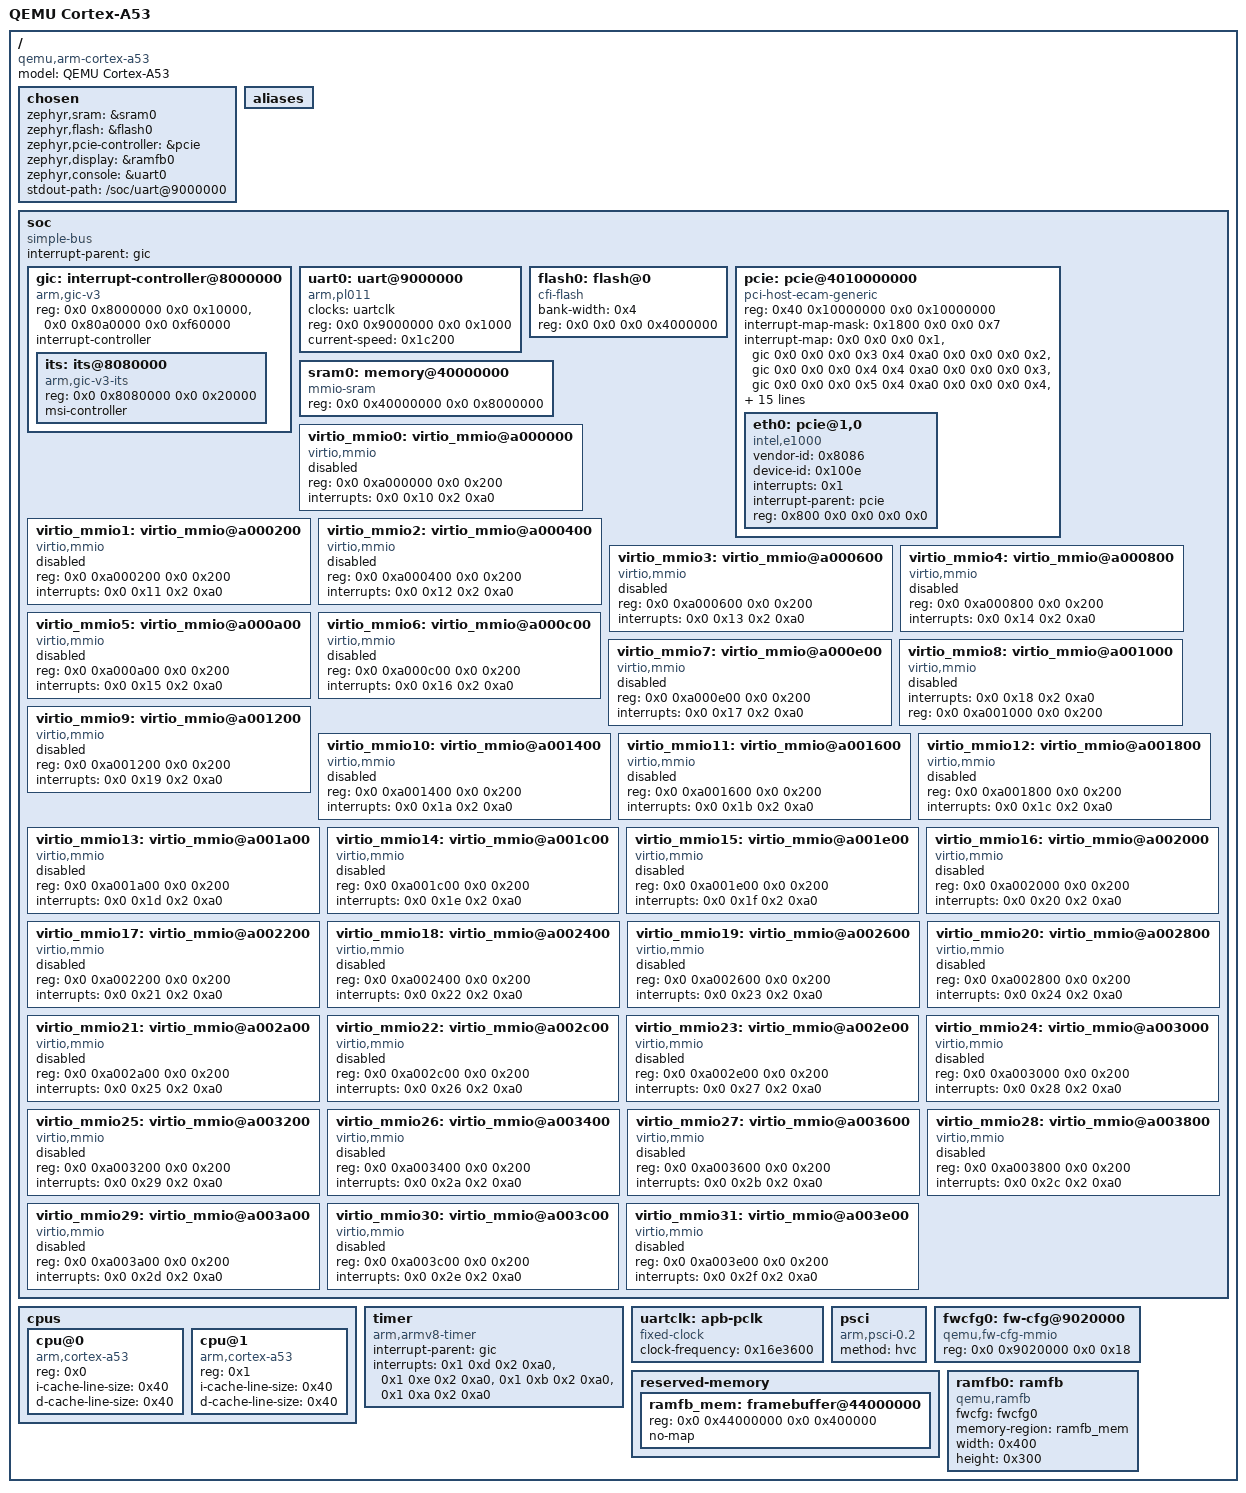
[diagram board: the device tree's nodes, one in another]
/dts-v1/;

/* node '/' defined in zephyr/dts/common/skeleton.dtsi:9 */
/ {
	#address-cells = < 0x2 >;           /* in zephyr/dts/arm64/qemu/qemu-virt-a53.dtsi:22 */
	#size-cells = < 0x2 >;              /* in zephyr/dts/arm64/qemu/qemu-virt-a53.dtsi:23 */
	model = "QEMU Cortex-A53";          /* in zephyr/boards/qemu/cortex_a53/qemu_cortex_a53.dts:12 */
	compatible = "qemu,arm-cortex-a53"; /* in zephyr/boards/qemu/cortex_a53/qemu_cortex_a53.dts:13 */

	/* node '/chosen' defined in zephyr/dts/common/skeleton.dtsi:13 */
	chosen {
		zephyr,sram = &sram0;              /* in zephyr/boards/qemu/cortex_a53/qemu_cortex_a53.dts:21 */
		zephyr,flash = &flash0;            /* in zephyr/boards/qemu/cortex_a53/qemu_cortex_a53.dts:24 */
		zephyr,pcie-controller = &pcie;    /* in zephyr/boards/qemu/cortex_a53/qemu_cortex_a53.dts:25 */
		zephyr,display = &ramfb0;          /* in zephyr/boards/qemu/cortex_a53/qemu_cortex_a53.dts:26 */
		zephyr,console = &uart0;           /* in ../../../../mnt/f/project/泉城实验室/tgoskits/configs/contest/zephyr/qemu-cortex-a53-pl011-polling.overlay:8 */
		stdout-path = "/soc/uart@9000000"; /* in ../../../../mnt/f/project/泉城实验室/tgoskits/configs/contest/zephyr/qemu-cortex-a53-pl011-polling.overlay:10 */
	};

	/* node '/aliases' defined in zephyr/dts/common/skeleton.dtsi:15 */
	aliases {
	};

	/* node '/soc' defined in zephyr/dts/arm64/armv8-a.dtsi:10 */
	soc {
		compatible = "simple-bus";   /* in zephyr/dts/arm64/armv8-a.dtsi:13 */
		#address-cells = < 0x2 >;    /* in zephyr/dts/arm64/qemu/qemu-virt-a53.dtsi:66 */
		#size-cells = < 0x2 >;       /* in zephyr/dts/arm64/qemu/qemu-virt-a53.dtsi:67 */
		ranges;                      /* in zephyr/dts/arm64/qemu/qemu-virt-a53.dtsi:68 */
		interrupt-parent = < &gic >; /* in zephyr/dts/arm64/qemu/qemu-virt-a53.dtsi:70 */

		/* node '/soc/interrupt-controller@8000000' defined in zephyr/dts/arm64/qemu/qemu-virt-a53.dtsi:72 */
		gic: interrupt-controller@8000000 {
			compatible = "arm,gic-v3",
			             "arm,gic";               /* in zephyr/dts/arm64/qemu/qemu-virt-a53.dtsi:73 */
			reg = < 0x0 0x8000000 0x0 0x10000 >,
			      < 0x0 0x80a0000 0x0 0xf60000 >; /* in zephyr/dts/arm64/qemu/qemu-virt-a53.dtsi:74 */
			interrupt-controller;                 /* in zephyr/dts/arm64/qemu/qemu-virt-a53.dtsi:76 */
			#interrupt-cells = < 0x4 >;           /* in zephyr/dts/arm64/qemu/qemu-virt-a53.dtsi:77 */
			status = "okay";                      /* in zephyr/dts/arm64/qemu/qemu-virt-a53.dtsi:78 */
			#size-cells = < 0x2 >;                /* in zephyr/dts/arm64/qemu/qemu-virt-a53.dtsi:79 */
			#address-cells = < 0x2 >;             /* in zephyr/dts/arm64/qemu/qemu-virt-a53.dtsi:80 */
			phandle = < 0x1 >;                    /* in zephyr/dts/arm64/qemu/qemu-virt-a53.dtsi:70 */

			/* node '/soc/interrupt-controller@8000000/its@8080000' defined in zephyr/dts/arm64/qemu/qemu-virt-a53.dtsi:82 */
			its: its@8080000 {
				compatible = "arm,gic-v3-its";       /* in zephyr/dts/arm64/qemu/qemu-virt-a53.dtsi:83 */
				reg = < 0x0 0x8080000 0x0 0x20000 >; /* in zephyr/dts/arm64/qemu/qemu-virt-a53.dtsi:84 */
				msi-controller;                      /* in zephyr/dts/arm64/qemu/qemu-virt-a53.dtsi:85 */
				phandle = < 0x3 >;                   /* in zephyr/dts/arm64/qemu/qemu-virt-a53.dtsi:151 */
			};
		};

		/* node '/soc/uart@9000000' defined in zephyr/dts/arm64/qemu/qemu-virt-a53.dtsi:89 */
		uart0: uart@9000000 {
			clocks = < &uartclk >;              /* in zephyr/dts/arm64/qemu/qemu-virt-a53.dtsi:95 */
			compatible = "arm,pl011";           /* in ../../../../mnt/f/project/泉城实验室/tgoskits/configs/contest/zephyr/qemu-cortex-a53-pl011-polling.overlay:15 */
			reg = < 0x0 0x9000000 0x0 0x1000 >; /* in ../../../../mnt/f/project/泉城实验室/tgoskits/configs/contest/zephyr/qemu-cortex-a53-pl011-polling.overlay:16 */
			current-speed = < 0x1c200 >;        /* in ../../../../mnt/f/project/泉城实验室/tgoskits/configs/contest/zephyr/qemu-cortex-a53-pl011-polling.overlay:17 */
			status = "okay";                    /* in ../../../../mnt/f/project/泉城实验室/tgoskits/configs/contest/zephyr/qemu-cortex-a53-pl011-polling.overlay:18 */
		};

		/* node '/soc/flash@0' defined in zephyr/dts/arm64/qemu/qemu-virt-a53.dtsi:98 */
		flash0: flash@0 {
			compatible = "cfi-flash";        /* in zephyr/dts/arm64/qemu/qemu-virt-a53.dtsi:99 */
			bank-width = < 0x4 >;            /* in zephyr/dts/arm64/qemu/qemu-virt-a53.dtsi:100 */
			reg = < 0x0 0x0 0x0 0x4000000 >; /* in zephyr/dts/arm64/qemu/qemu-virt-a53.dtsi:105 */
		};

		/* node '/soc/pcie@4010000000' defined in zephyr/dts/arm64/qemu/qemu-virt-a53.dtsi:108 */
		pcie: pcie@4010000000 {
			compatible = "pci-host-ecam-generic";                                                                 /* in zephyr/dts/arm64/qemu/qemu-virt-a53.dtsi:109 */
			device_type = "pci";                                                                                  /* in zephyr/dts/arm64/qemu/qemu-virt-a53.dtsi:110 */
			reg = < 0x40 0x10000000 0x0 0x10000000 >;                                                             /* in zephyr/dts/arm64/qemu/qemu-virt-a53.dtsi:111 */
			#size-cells = < 0x2 >;                                                                                /* in zephyr/dts/arm64/qemu/qemu-virt-a53.dtsi:112 */
			#address-cells = < 0x3 >;                                                                             /* in zephyr/dts/arm64/qemu/qemu-virt-a53.dtsi:113 */
			ranges = < 0x1000000 0x0 0x0 0x0 0x3eff0000 0x0 0x10000 0x2000000 0x0 0x10000000 0x0 0x10000000
			           0x0 0x2eff0000 0x3000000 0x80 0x0 0x80 0x0 0x80 0x0 >;                                     /* in zephyr/dts/arm64/qemu/qemu-virt-a53.dtsi:114 */
			#interrupt-cells = < 0x1 >;                                                                           /* in zephyr/dts/arm64/qemu/qemu-virt-a53.dtsi:117 */
			interrupt-map-mask = < 0x1800 0x0 0x0 0x7 >;                                                          /* in zephyr/dts/arm64/qemu/qemu-virt-a53.dtsi:118 */
			interrupt-map = < 0x0 0x0 0x0 0x1 &gic 0x0 0x0 0x0 0x3 0x4 0xa0 0x0 0x0 0x0 0x2 &gic 0x0 0x0 0x0 0x4
			                  0x4 0xa0 0x0 0x0 0x0 0x3 &gic 0x0 0x0 0x0 0x5 0x4 0xa0 0x0 0x0 0x0 0x4 &gic 0x0 0x0
			                  0x0 0x6 0x4 0xa0 0x800 0x0 0x0 0x1 &gic 0x0 0x0 0x0 0x4 0x4 0xa0 0x800 0x0 0x0 0x2
			                  &gic 0x0 0x0 0x0 0x5 0x4 0xa0 0x800 0x0 0x0 0x3 &gic 0x0 0x0 0x0 0x6 0x4 0xa0 0x800
			                  0x0 0x0 0x4 &gic 0x0 0x0 0x0 0x3 0x4 0xa0 0x1000 0x0 0x0 0x1 &gic 0x0 0x0 0x0 0x5
			                  0x4 0xa0 0x1000 0x0 0x0 0x2 &gic 0x0 0x0 0x0 0x6 0x4 0xa0 0x1000 0x0 0x0 0x3 &gic
			                  0x0 0x0 0x0 0x3 0x4 0xa0 0x1000 0x0 0x0 0x4 &gic 0x0 0x0 0x0 0x4 0x4 0xa0 0x1800
			                  0x0 0x0 0x1 &gic 0x0 0x0 0x0 0x6 0x4 0xa0 0x1800 0x0 0x0 0x2 &gic 0x0 0x0 0x0 0x3
			                  0x4 0xa0 0x1800 0x0 0x0 0x3 &gic 0x0 0x0 0x0 0x4 0x4 0xa0 0x1800 0x0 0x0 0x4 &gic
			                  0x0 0x0 0x0 0x5 0x4 0xa0 >;                                                         /* in zephyr/dts/arm64/qemu/qemu-virt-a53.dtsi:119 */
			msi-parent = < &its >;                                                                                /* in zephyr/dts/arm64/qemu/qemu-virt-a53.dtsi:151 */
			bus-range = < 0x0 0xff >;                                                                             /* in zephyr/dts/arm64/qemu/qemu-virt-a53.dtsi:152 */
			phandle = < 0x4 >;                                                                                    /* in zephyr/boards/qemu/cortex_a53/qemu_cortex_a53.dts:298 */

			/* node '/soc/pcie@4010000000/pcie@1,0' defined in zephyr/boards/qemu/cortex_a53/qemu_cortex_a53.dts:293 */
			eth0: pcie@1,0 {
				compatible = "intel,e1000";      /* in zephyr/boards/qemu/cortex_a53/qemu_cortex_a53.dts:294 */
				vendor-id = < 0x8086 >;          /* in zephyr/boards/qemu/cortex_a53/qemu_cortex_a53.dts:295 */
				device-id = < 0x100e >;          /* in zephyr/boards/qemu/cortex_a53/qemu_cortex_a53.dts:296 */
				interrupts = < 0x1 >;            /* in zephyr/boards/qemu/cortex_a53/qemu_cortex_a53.dts:297 */
				interrupt-parent = < &pcie >;    /* in zephyr/boards/qemu/cortex_a53/qemu_cortex_a53.dts:298 */
				reg = < 0x800 0x0 0x0 0x0 0x0 >; /* in zephyr/boards/qemu/cortex_a53/qemu_cortex_a53.dts:299 */
				status = "okay";                 /* in zephyr/boards/qemu/cortex_a53/qemu_cortex_a53.dts:300 */
			};
		};

		/* node '/soc/memory@40000000' defined in zephyr/boards/qemu/cortex_a53/qemu_cortex_a53.dts:30 */
		sram0: memory@40000000 {
			compatible = "mmio-sram";               /* in zephyr/boards/qemu/cortex_a53/qemu_cortex_a53.dts:31 */
			reg = < 0x0 0x40000000 0x0 0x8000000 >; /* in zephyr/boards/qemu/cortex_a53/qemu_cortex_a53.dts:32 */
		};

		/* node '/soc/virtio_mmio@a000000' defined in zephyr/boards/qemu/cortex_a53/qemu_cortex_a53.dts:35 */
		virtio_mmio0: virtio_mmio@a000000 {
			compatible = "virtio,mmio";         /* in zephyr/boards/qemu/cortex_a53/qemu_cortex_a53.dts:36 */
			reg = < 0x0 0xa000000 0x0 0x200 >;  /* in zephyr/boards/qemu/cortex_a53/qemu_cortex_a53.dts:37 */
			interrupts = < 0x0 0x10 0x2 0xa0 >; /* in zephyr/boards/qemu/cortex_a53/qemu_cortex_a53.dts:38 */
			status = "disabled";                /* in zephyr/boards/qemu/cortex_a53/qemu_cortex_a53.dts:39 */
		};

		/* node '/soc/virtio_mmio@a000200' defined in zephyr/boards/qemu/cortex_a53/qemu_cortex_a53.dts:42 */
		virtio_mmio1: virtio_mmio@a000200 {
			compatible = "virtio,mmio";         /* in zephyr/boards/qemu/cortex_a53/qemu_cortex_a53.dts:43 */
			reg = < 0x0 0xa000200 0x0 0x200 >;  /* in zephyr/boards/qemu/cortex_a53/qemu_cortex_a53.dts:44 */
			interrupts = < 0x0 0x11 0x2 0xa0 >; /* in zephyr/boards/qemu/cortex_a53/qemu_cortex_a53.dts:45 */
			status = "disabled";                /* in zephyr/boards/qemu/cortex_a53/qemu_cortex_a53.dts:46 */
		};

		/* node '/soc/virtio_mmio@a000400' defined in zephyr/boards/qemu/cortex_a53/qemu_cortex_a53.dts:49 */
		virtio_mmio2: virtio_mmio@a000400 {
			compatible = "virtio,mmio";         /* in zephyr/boards/qemu/cortex_a53/qemu_cortex_a53.dts:50 */
			reg = < 0x0 0xa000400 0x0 0x200 >;  /* in zephyr/boards/qemu/cortex_a53/qemu_cortex_a53.dts:51 */
			interrupts = < 0x0 0x12 0x2 0xa0 >; /* in zephyr/boards/qemu/cortex_a53/qemu_cortex_a53.dts:52 */
			status = "disabled";                /* in zephyr/boards/qemu/cortex_a53/qemu_cortex_a53.dts:53 */
		};

		/* node '/soc/virtio_mmio@a000600' defined in zephyr/boards/qemu/cortex_a53/qemu_cortex_a53.dts:56 */
		virtio_mmio3: virtio_mmio@a000600 {
			compatible = "virtio,mmio";         /* in zephyr/boards/qemu/cortex_a53/qemu_cortex_a53.dts:57 */
			reg = < 0x0 0xa000600 0x0 0x200 >;  /* in zephyr/boards/qemu/cortex_a53/qemu_cortex_a53.dts:58 */
			interrupts = < 0x0 0x13 0x2 0xa0 >; /* in zephyr/boards/qemu/cortex_a53/qemu_cortex_a53.dts:59 */
			status = "disabled";                /* in zephyr/boards/qemu/cortex_a53/qemu_cortex_a53.dts:60 */
		};

		/* node '/soc/virtio_mmio@a000800' defined in zephyr/boards/qemu/cortex_a53/qemu_cortex_a53.dts:63 */
		virtio_mmio4: virtio_mmio@a000800 {
			compatible = "virtio,mmio";         /* in zephyr/boards/qemu/cortex_a53/qemu_cortex_a53.dts:64 */
			reg = < 0x0 0xa000800 0x0 0x200 >;  /* in zephyr/boards/qemu/cortex_a53/qemu_cortex_a53.dts:65 */
			interrupts = < 0x0 0x14 0x2 0xa0 >; /* in zephyr/boards/qemu/cortex_a53/qemu_cortex_a53.dts:66 */
			status = "disabled";                /* in zephyr/boards/qemu/cortex_a53/qemu_cortex_a53.dts:67 */
		};

		/* node '/soc/virtio_mmio@a000a00' defined in zephyr/boards/qemu/cortex_a53/qemu_cortex_a53.dts:70 */
		virtio_mmio5: virtio_mmio@a000a00 {
			compatible = "virtio,mmio";         /* in zephyr/boards/qemu/cortex_a53/qemu_cortex_a53.dts:71 */
			reg = < 0x0 0xa000a00 0x0 0x200 >;  /* in zephyr/boards/qemu/cortex_a53/qemu_cortex_a53.dts:72 */
			interrupts = < 0x0 0x15 0x2 0xa0 >; /* in zephyr/boards/qemu/cortex_a53/qemu_cortex_a53.dts:73 */
			status = "disabled";                /* in zephyr/boards/qemu/cortex_a53/qemu_cortex_a53.dts:74 */
		};

		/* node '/soc/virtio_mmio@a000c00' defined in zephyr/boards/qemu/cortex_a53/qemu_cortex_a53.dts:77 */
		virtio_mmio6: virtio_mmio@a000c00 {
			compatible = "virtio,mmio";         /* in zephyr/boards/qemu/cortex_a53/qemu_cortex_a53.dts:78 */
			reg = < 0x0 0xa000c00 0x0 0x200 >;  /* in zephyr/boards/qemu/cortex_a53/qemu_cortex_a53.dts:79 */
			interrupts = < 0x0 0x16 0x2 0xa0 >; /* in zephyr/boards/qemu/cortex_a53/qemu_cortex_a53.dts:80 */
			status = "disabled";                /* in zephyr/boards/qemu/cortex_a53/qemu_cortex_a53.dts:81 */
		};

		/* node '/soc/virtio_mmio@a000e00' defined in zephyr/boards/qemu/cortex_a53/qemu_cortex_a53.dts:84 */
		virtio_mmio7: virtio_mmio@a000e00 {
			compatible = "virtio,mmio";         /* in zephyr/boards/qemu/cortex_a53/qemu_cortex_a53.dts:85 */
			reg = < 0x0 0xa000e00 0x0 0x200 >;  /* in zephyr/boards/qemu/cortex_a53/qemu_cortex_a53.dts:86 */
			interrupts = < 0x0 0x17 0x2 0xa0 >; /* in zephyr/boards/qemu/cortex_a53/qemu_cortex_a53.dts:87 */
			status = "disabled";                /* in zephyr/boards/qemu/cortex_a53/qemu_cortex_a53.dts:88 */
		};

		/* node '/soc/virtio_mmio@a001000' defined in zephyr/boards/qemu/cortex_a53/qemu_cortex_a53.dts:91 */
		virtio_mmio8: virtio_mmio@a001000 {
			compatible = "virtio,mmio";         /* in zephyr/boards/qemu/cortex_a53/qemu_cortex_a53.dts:92 */
			interrupts = < 0x0 0x18 0x2 0xa0 >; /* in zephyr/boards/qemu/cortex_a53/qemu_cortex_a53.dts:93 */
			reg = < 0x0 0xa001000 0x0 0x200 >;  /* in zephyr/boards/qemu/cortex_a53/qemu_cortex_a53.dts:94 */
			status = "disabled";                /* in zephyr/boards/qemu/cortex_a53/qemu_cortex_a53.dts:95 */
		};

		/* node '/soc/virtio_mmio@a001200' defined in zephyr/boards/qemu/cortex_a53/qemu_cortex_a53.dts:98 */
		virtio_mmio9: virtio_mmio@a001200 {
			compatible = "virtio,mmio";         /* in zephyr/boards/qemu/cortex_a53/qemu_cortex_a53.dts:99 */
			reg = < 0x0 0xa001200 0x0 0x200 >;  /* in zephyr/boards/qemu/cortex_a53/qemu_cortex_a53.dts:100 */
			interrupts = < 0x0 0x19 0x2 0xa0 >; /* in zephyr/boards/qemu/cortex_a53/qemu_cortex_a53.dts:101 */
			status = "disabled";                /* in zephyr/boards/qemu/cortex_a53/qemu_cortex_a53.dts:102 */
		};

		/* node '/soc/virtio_mmio@a001400' defined in zephyr/boards/qemu/cortex_a53/qemu_cortex_a53.dts:105 */
		virtio_mmio10: virtio_mmio@a001400 {
			compatible = "virtio,mmio";         /* in zephyr/boards/qemu/cortex_a53/qemu_cortex_a53.dts:106 */
			reg = < 0x0 0xa001400 0x0 0x200 >;  /* in zephyr/boards/qemu/cortex_a53/qemu_cortex_a53.dts:107 */
			interrupts = < 0x0 0x1a 0x2 0xa0 >; /* in zephyr/boards/qemu/cortex_a53/qemu_cortex_a53.dts:108 */
			status = "disabled";                /* in zephyr/boards/qemu/cortex_a53/qemu_cortex_a53.dts:109 */
		};

		/* node '/soc/virtio_mmio@a001600' defined in zephyr/boards/qemu/cortex_a53/qemu_cortex_a53.dts:112 */
		virtio_mmio11: virtio_mmio@a001600 {
			compatible = "virtio,mmio";         /* in zephyr/boards/qemu/cortex_a53/qemu_cortex_a53.dts:113 */
			reg = < 0x0 0xa001600 0x0 0x200 >;  /* in zephyr/boards/qemu/cortex_a53/qemu_cortex_a53.dts:114 */
			interrupts = < 0x0 0x1b 0x2 0xa0 >; /* in zephyr/boards/qemu/cortex_a53/qemu_cortex_a53.dts:115 */
			status = "disabled";                /* in zephyr/boards/qemu/cortex_a53/qemu_cortex_a53.dts:116 */
		};

		/* node '/soc/virtio_mmio@a001800' defined in zephyr/boards/qemu/cortex_a53/qemu_cortex_a53.dts:119 */
		virtio_mmio12: virtio_mmio@a001800 {
			compatible = "virtio,mmio";         /* in zephyr/boards/qemu/cortex_a53/qemu_cortex_a53.dts:120 */
			reg = < 0x0 0xa001800 0x0 0x200 >;  /* in zephyr/boards/qemu/cortex_a53/qemu_cortex_a53.dts:121 */
			interrupts = < 0x0 0x1c 0x2 0xa0 >; /* in zephyr/boards/qemu/cortex_a53/qemu_cortex_a53.dts:122 */
			status = "disabled";                /* in zephyr/boards/qemu/cortex_a53/qemu_cortex_a53.dts:123 */
		};

		/* node '/soc/virtio_mmio@a001a00' defined in zephyr/boards/qemu/cortex_a53/qemu_cortex_a53.dts:126 */
		virtio_mmio13: virtio_mmio@a001a00 {
			compatible = "virtio,mmio";         /* in zephyr/boards/qemu/cortex_a53/qemu_cortex_a53.dts:127 */
			reg = < 0x0 0xa001a00 0x0 0x200 >;  /* in zephyr/boards/qemu/cortex_a53/qemu_cortex_a53.dts:128 */
			interrupts = < 0x0 0x1d 0x2 0xa0 >; /* in zephyr/boards/qemu/cortex_a53/qemu_cortex_a53.dts:129 */
			status = "disabled";                /* in zephyr/boards/qemu/cortex_a53/qemu_cortex_a53.dts:130 */
		};

		/* node '/soc/virtio_mmio@a001c00' defined in zephyr/boards/qemu/cortex_a53/qemu_cortex_a53.dts:133 */
		virtio_mmio14: virtio_mmio@a001c00 {
			compatible = "virtio,mmio";         /* in zephyr/boards/qemu/cortex_a53/qemu_cortex_a53.dts:134 */
			reg = < 0x0 0xa001c00 0x0 0x200 >;  /* in zephyr/boards/qemu/cortex_a53/qemu_cortex_a53.dts:135 */
			interrupts = < 0x0 0x1e 0x2 0xa0 >; /* in zephyr/boards/qemu/cortex_a53/qemu_cortex_a53.dts:136 */
			status = "disabled";                /* in zephyr/boards/qemu/cortex_a53/qemu_cortex_a53.dts:137 */
		};

		/* node '/soc/virtio_mmio@a001e00' defined in zephyr/boards/qemu/cortex_a53/qemu_cortex_a53.dts:140 */
		virtio_mmio15: virtio_mmio@a001e00 {
			compatible = "virtio,mmio";         /* in zephyr/boards/qemu/cortex_a53/qemu_cortex_a53.dts:141 */
			reg = < 0x0 0xa001e00 0x0 0x200 >;  /* in zephyr/boards/qemu/cortex_a53/qemu_cortex_a53.dts:142 */
			interrupts = < 0x0 0x1f 0x2 0xa0 >; /* in zephyr/boards/qemu/cortex_a53/qemu_cortex_a53.dts:143 */
			status = "disabled";                /* in zephyr/boards/qemu/cortex_a53/qemu_cortex_a53.dts:144 */
		};

		/* node '/soc/virtio_mmio@a002000' defined in zephyr/boards/qemu/cortex_a53/qemu_cortex_a53.dts:147 */
		virtio_mmio16: virtio_mmio@a002000 {
			compatible = "virtio,mmio";         /* in zephyr/boards/qemu/cortex_a53/qemu_cortex_a53.dts:148 */
			reg = < 0x0 0xa002000 0x0 0x200 >;  /* in zephyr/boards/qemu/cortex_a53/qemu_cortex_a53.dts:149 */
			interrupts = < 0x0 0x20 0x2 0xa0 >; /* in zephyr/boards/qemu/cortex_a53/qemu_cortex_a53.dts:150 */
			status = "disabled";                /* in zephyr/boards/qemu/cortex_a53/qemu_cortex_a53.dts:151 */
		};

		/* node '/soc/virtio_mmio@a002200' defined in zephyr/boards/qemu/cortex_a53/qemu_cortex_a53.dts:154 */
		virtio_mmio17: virtio_mmio@a002200 {
			compatible = "virtio,mmio";         /* in zephyr/boards/qemu/cortex_a53/qemu_cortex_a53.dts:155 */
			reg = < 0x0 0xa002200 0x0 0x200 >;  /* in zephyr/boards/qemu/cortex_a53/qemu_cortex_a53.dts:156 */
			interrupts = < 0x0 0x21 0x2 0xa0 >; /* in zephyr/boards/qemu/cortex_a53/qemu_cortex_a53.dts:157 */
			status = "disabled";                /* in zephyr/boards/qemu/cortex_a53/qemu_cortex_a53.dts:158 */
		};

		/* node '/soc/virtio_mmio@a002400' defined in zephyr/boards/qemu/cortex_a53/qemu_cortex_a53.dts:161 */
		virtio_mmio18: virtio_mmio@a002400 {
			compatible = "virtio,mmio";         /* in zephyr/boards/qemu/cortex_a53/qemu_cortex_a53.dts:162 */
			reg = < 0x0 0xa002400 0x0 0x200 >;  /* in zephyr/boards/qemu/cortex_a53/qemu_cortex_a53.dts:163 */
			interrupts = < 0x0 0x22 0x2 0xa0 >; /* in zephyr/boards/qemu/cortex_a53/qemu_cortex_a53.dts:164 */
			status = "disabled";                /* in zephyr/boards/qemu/cortex_a53/qemu_cortex_a53.dts:165 */
		};

		/* node '/soc/virtio_mmio@a002600' defined in zephyr/boards/qemu/cortex_a53/qemu_cortex_a53.dts:168 */
		virtio_mmio19: virtio_mmio@a002600 {
			compatible = "virtio,mmio";         /* in zephyr/boards/qemu/cortex_a53/qemu_cortex_a53.dts:169 */
			reg = < 0x0 0xa002600 0x0 0x200 >;  /* in zephyr/boards/qemu/cortex_a53/qemu_cortex_a53.dts:170 */
			interrupts = < 0x0 0x23 0x2 0xa0 >; /* in zephyr/boards/qemu/cortex_a53/qemu_cortex_a53.dts:171 */
			status = "disabled";                /* in zephyr/boards/qemu/cortex_a53/qemu_cortex_a53.dts:172 */
		};

		/* node '/soc/virtio_mmio@a002800' defined in zephyr/boards/qemu/cortex_a53/qemu_cortex_a53.dts:175 */
		virtio_mmio20: virtio_mmio@a002800 {
			compatible = "virtio,mmio";         /* in zephyr/boards/qemu/cortex_a53/qemu_cortex_a53.dts:176 */
			reg = < 0x0 0xa002800 0x0 0x200 >;  /* in zephyr/boards/qemu/cortex_a53/qemu_cortex_a53.dts:177 */
			interrupts = < 0x0 0x24 0x2 0xa0 >; /* in zephyr/boards/qemu/cortex_a53/qemu_cortex_a53.dts:178 */
			status = "disabled";                /* in zephyr/boards/qemu/cortex_a53/qemu_cortex_a53.dts:179 */
		};

		/* node '/soc/virtio_mmio@a002a00' defined in zephyr/boards/qemu/cortex_a53/qemu_cortex_a53.dts:182 */
		virtio_mmio21: virtio_mmio@a002a00 {
			compatible = "virtio,mmio";         /* in zephyr/boards/qemu/cortex_a53/qemu_cortex_a53.dts:183 */
			reg = < 0x0 0xa002a00 0x0 0x200 >;  /* in zephyr/boards/qemu/cortex_a53/qemu_cortex_a53.dts:184 */
			interrupts = < 0x0 0x25 0x2 0xa0 >; /* in zephyr/boards/qemu/cortex_a53/qemu_cortex_a53.dts:185 */
			status = "disabled";                /* in zephyr/boards/qemu/cortex_a53/qemu_cortex_a53.dts:186 */
		};

		/* node '/soc/virtio_mmio@a002c00' defined in zephyr/boards/qemu/cortex_a53/qemu_cortex_a53.dts:189 */
		virtio_mmio22: virtio_mmio@a002c00 {
			compatible = "virtio,mmio";         /* in zephyr/boards/qemu/cortex_a53/qemu_cortex_a53.dts:190 */
			reg = < 0x0 0xa002c00 0x0 0x200 >;  /* in zephyr/boards/qemu/cortex_a53/qemu_cortex_a53.dts:191 */
			interrupts = < 0x0 0x26 0x2 0xa0 >; /* in zephyr/boards/qemu/cortex_a53/qemu_cortex_a53.dts:192 */
			status = "disabled";                /* in zephyr/boards/qemu/cortex_a53/qemu_cortex_a53.dts:193 */
		};

		/* node '/soc/virtio_mmio@a002e00' defined in zephyr/boards/qemu/cortex_a53/qemu_cortex_a53.dts:196 */
		virtio_mmio23: virtio_mmio@a002e00 {
			compatible = "virtio,mmio";         /* in zephyr/boards/qemu/cortex_a53/qemu_cortex_a53.dts:197 */
			reg = < 0x0 0xa002e00 0x0 0x200 >;  /* in zephyr/boards/qemu/cortex_a53/qemu_cortex_a53.dts:198 */
			interrupts = < 0x0 0x27 0x2 0xa0 >; /* in zephyr/boards/qemu/cortex_a53/qemu_cortex_a53.dts:199 */
			status = "disabled";                /* in zephyr/boards/qemu/cortex_a53/qemu_cortex_a53.dts:200 */
		};

		/* node '/soc/virtio_mmio@a003000' defined in zephyr/boards/qemu/cortex_a53/qemu_cortex_a53.dts:203 */
		virtio_mmio24: virtio_mmio@a003000 {
			compatible = "virtio,mmio";         /* in zephyr/boards/qemu/cortex_a53/qemu_cortex_a53.dts:204 */
			reg = < 0x0 0xa003000 0x0 0x200 >;  /* in zephyr/boards/qemu/cortex_a53/qemu_cortex_a53.dts:205 */
			interrupts = < 0x0 0x28 0x2 0xa0 >; /* in zephyr/boards/qemu/cortex_a53/qemu_cortex_a53.dts:206 */
			status = "disabled";                /* in zephyr/boards/qemu/cortex_a53/qemu_cortex_a53.dts:207 */
		};

		/* node '/soc/virtio_mmio@a003200' defined in zephyr/boards/qemu/cortex_a53/qemu_cortex_a53.dts:210 */
		virtio_mmio25: virtio_mmio@a003200 {
			compatible = "virtio,mmio";         /* in zephyr/boards/qemu/cortex_a53/qemu_cortex_a53.dts:211 */
			reg = < 0x0 0xa003200 0x0 0x200 >;  /* in zephyr/boards/qemu/cortex_a53/qemu_cortex_a53.dts:212 */
			interrupts = < 0x0 0x29 0x2 0xa0 >; /* in zephyr/boards/qemu/cortex_a53/qemu_cortex_a53.dts:213 */
			status = "disabled";                /* in zephyr/boards/qemu/cortex_a53/qemu_cortex_a53.dts:214 */
		};

		/* node '/soc/virtio_mmio@a003400' defined in zephyr/boards/qemu/cortex_a53/qemu_cortex_a53.dts:217 */
		virtio_mmio26: virtio_mmio@a003400 {
			compatible = "virtio,mmio";         /* in zephyr/boards/qemu/cortex_a53/qemu_cortex_a53.dts:218 */
			reg = < 0x0 0xa003400 0x0 0x200 >;  /* in zephyr/boards/qemu/cortex_a53/qemu_cortex_a53.dts:219 */
			interrupts = < 0x0 0x2a 0x2 0xa0 >; /* in zephyr/boards/qemu/cortex_a53/qemu_cortex_a53.dts:220 */
			status = "disabled";                /* in zephyr/boards/qemu/cortex_a53/qemu_cortex_a53.dts:221 */
		};

		/* node '/soc/virtio_mmio@a003600' defined in zephyr/boards/qemu/cortex_a53/qemu_cortex_a53.dts:224 */
		virtio_mmio27: virtio_mmio@a003600 {
			compatible = "virtio,mmio";         /* in zephyr/boards/qemu/cortex_a53/qemu_cortex_a53.dts:225 */
			reg = < 0x0 0xa003600 0x0 0x200 >;  /* in zephyr/boards/qemu/cortex_a53/qemu_cortex_a53.dts:226 */
			interrupts = < 0x0 0x2b 0x2 0xa0 >; /* in zephyr/boards/qemu/cortex_a53/qemu_cortex_a53.dts:227 */
			status = "disabled";                /* in zephyr/boards/qemu/cortex_a53/qemu_cortex_a53.dts:228 */
		};

		/* node '/soc/virtio_mmio@a003800' defined in zephyr/boards/qemu/cortex_a53/qemu_cortex_a53.dts:231 */
		virtio_mmio28: virtio_mmio@a003800 {
			compatible = "virtio,mmio";         /* in zephyr/boards/qemu/cortex_a53/qemu_cortex_a53.dts:232 */
			reg = < 0x0 0xa003800 0x0 0x200 >;  /* in zephyr/boards/qemu/cortex_a53/qemu_cortex_a53.dts:233 */
			interrupts = < 0x0 0x2c 0x2 0xa0 >; /* in zephyr/boards/qemu/cortex_a53/qemu_cortex_a53.dts:234 */
			status = "disabled";                /* in zephyr/boards/qemu/cortex_a53/qemu_cortex_a53.dts:235 */
		};

		/* node '/soc/virtio_mmio@a003a00' defined in zephyr/boards/qemu/cortex_a53/qemu_cortex_a53.dts:238 */
		virtio_mmio29: virtio_mmio@a003a00 {
			compatible = "virtio,mmio";         /* in zephyr/boards/qemu/cortex_a53/qemu_cortex_a53.dts:239 */
			reg = < 0x0 0xa003a00 0x0 0x200 >;  /* in zephyr/boards/qemu/cortex_a53/qemu_cortex_a53.dts:240 */
			interrupts = < 0x0 0x2d 0x2 0xa0 >; /* in zephyr/boards/qemu/cortex_a53/qemu_cortex_a53.dts:241 */
			status = "disabled";                /* in zephyr/boards/qemu/cortex_a53/qemu_cortex_a53.dts:242 */
		};

		/* node '/soc/virtio_mmio@a003c00' defined in zephyr/boards/qemu/cortex_a53/qemu_cortex_a53.dts:245 */
		virtio_mmio30: virtio_mmio@a003c00 {
			compatible = "virtio,mmio";         /* in zephyr/boards/qemu/cortex_a53/qemu_cortex_a53.dts:246 */
			reg = < 0x0 0xa003c00 0x0 0x200 >;  /* in zephyr/boards/qemu/cortex_a53/qemu_cortex_a53.dts:247 */
			interrupts = < 0x0 0x2e 0x2 0xa0 >; /* in zephyr/boards/qemu/cortex_a53/qemu_cortex_a53.dts:248 */
			status = "disabled";                /* in zephyr/boards/qemu/cortex_a53/qemu_cortex_a53.dts:249 */
		};

		/* node '/soc/virtio_mmio@a003e00' defined in zephyr/boards/qemu/cortex_a53/qemu_cortex_a53.dts:252 */
		virtio_mmio31: virtio_mmio@a003e00 {
			compatible = "virtio,mmio";         /* in zephyr/boards/qemu/cortex_a53/qemu_cortex_a53.dts:253 */
			reg = < 0x0 0xa003e00 0x0 0x200 >;  /* in zephyr/boards/qemu/cortex_a53/qemu_cortex_a53.dts:254 */
			interrupts = < 0x0 0x2f 0x2 0xa0 >; /* in zephyr/boards/qemu/cortex_a53/qemu_cortex_a53.dts:255 */
			status = "disabled";                /* in zephyr/boards/qemu/cortex_a53/qemu_cortex_a53.dts:256 */
		};
	};

	/* node '/cpus' defined in zephyr/dts/arm64/qemu/qemu-virt-a53.dtsi:25 */
	cpus {
		#address-cells = < 0x1 >; /* in zephyr/dts/arm64/qemu/qemu-virt-a53.dtsi:26 */
		#size-cells = < 0x0 >;    /* in zephyr/dts/arm64/qemu/qemu-virt-a53.dtsi:27 */

		/* node '/cpus/cpu@0' defined in zephyr/dts/arm64/qemu/qemu-virt-a53.dtsi:29 */
		cpu@0 {
			device_type = "cpu";           /* in zephyr/dts/arm64/qemu/qemu-virt-a53.dtsi:30 */
			compatible = "arm,cortex-a53"; /* in zephyr/dts/arm64/qemu/qemu-virt-a53.dtsi:31 */
			reg = < 0x0 >;                 /* in zephyr/dts/arm64/qemu/qemu-virt-a53.dtsi:32 */
			i-cache-line-size = < 0x40 >;  /* in zephyr/dts/arm64/qemu/qemu-virt-a53.dtsi:33 */
			d-cache-line-size = < 0x40 >;  /* in zephyr/dts/arm64/qemu/qemu-virt-a53.dtsi:34 */
		};

		/* node '/cpus/cpu@1' defined in zephyr/dts/arm64/qemu/qemu-virt-a53.dtsi:37 */
		cpu@1 {
			device_type = "cpu";           /* in zephyr/dts/arm64/qemu/qemu-virt-a53.dtsi:38 */
			compatible = "arm,cortex-a53"; /* in zephyr/dts/arm64/qemu/qemu-virt-a53.dtsi:39 */
			reg = < 0x1 >;                 /* in zephyr/dts/arm64/qemu/qemu-virt-a53.dtsi:40 */
			i-cache-line-size = < 0x40 >;  /* in zephyr/dts/arm64/qemu/qemu-virt-a53.dtsi:41 */
			d-cache-line-size = < 0x40 >;  /* in zephyr/dts/arm64/qemu/qemu-virt-a53.dtsi:42 */
		};
	};

	/* node '/timer' defined in zephyr/dts/arm64/qemu/qemu-virt-a53.dtsi:46 */
	timer {
		compatible = "arm,armv8-timer";    /* in zephyr/dts/arm64/qemu/qemu-virt-a53.dtsi:47 */
		interrupt-parent = < &gic >;       /* in zephyr/dts/arm64/qemu/qemu-virt-a53.dtsi:48 */
		interrupts = < 0x1 0xd 0x2 0xa0 >,
		             < 0x1 0xe 0x2 0xa0 >,
		             < 0x1 0xb 0x2 0xa0 >,
		             < 0x1 0xa 0x2 0xa0 >; /* in zephyr/dts/arm64/qemu/qemu-virt-a53.dtsi:49 */
	};

	/* node '/apb-pclk' defined in zephyr/dts/arm64/qemu/qemu-virt-a53.dtsi:59 */
	uartclk: apb-pclk {
		compatible = "fixed-clock";      /* in zephyr/dts/arm64/qemu/qemu-virt-a53.dtsi:60 */
		clock-frequency = < 0x16e3600 >; /* in zephyr/dts/arm64/qemu/qemu-virt-a53.dtsi:61 */
		#clock-cells = < 0x0 >;          /* in zephyr/dts/arm64/qemu/qemu-virt-a53.dtsi:62 */
		phandle = < 0x2 >;               /* in zephyr/dts/arm64/qemu/qemu-virt-a53.dtsi:95 */
	};

	/* node '/psci' defined in zephyr/boards/qemu/cortex_a53/qemu_cortex_a53.dts:15 */
	psci {
		compatible = "arm,psci-0.2"; /* in zephyr/boards/qemu/cortex_a53/qemu_cortex_a53.dts:16 */
		method = "hvc";              /* in zephyr/boards/qemu/cortex_a53/qemu_cortex_a53.dts:17 */
	};

	/* node '/fw-cfg@9020000' defined in zephyr/boards/qemu/cortex_a53/qemu_cortex_a53.dts:260 */
	fwcfg0: fw-cfg@9020000 {
		compatible = "qemu,fw-cfg-mmio";  /* in zephyr/boards/qemu/cortex_a53/qemu_cortex_a53.dts:261 */
		reg = < 0x0 0x9020000 0x0 0x18 >; /* in zephyr/boards/qemu/cortex_a53/qemu_cortex_a53.dts:262 */
		status = "okay";                  /* in zephyr/boards/qemu/cortex_a53/qemu_cortex_a53.dts:263 */
		phandle = < 0x5 >;                /* in zephyr/boards/qemu/cortex_a53/qemu_cortex_a53.dts:279 */
	};

	/* node '/reserved-memory' defined in zephyr/boards/qemu/cortex_a53/qemu_cortex_a53.dts:266 */
	reserved-memory {
		#address-cells = < 0x2 >; /* in zephyr/boards/qemu/cortex_a53/qemu_cortex_a53.dts:267 */
		#size-cells = < 0x2 >;    /* in zephyr/boards/qemu/cortex_a53/qemu_cortex_a53.dts:268 */
		ranges;                   /* in zephyr/boards/qemu/cortex_a53/qemu_cortex_a53.dts:269 */

		/* node '/reserved-memory/framebuffer@44000000' defined in zephyr/boards/qemu/cortex_a53/qemu_cortex_a53.dts:271 */
		ramfb_mem: framebuffer@44000000 {
			reg = < 0x0 0x44000000 0x0 0x400000 >; /* in zephyr/boards/qemu/cortex_a53/qemu_cortex_a53.dts:272 */
			no-map;                                /* in zephyr/boards/qemu/cortex_a53/qemu_cortex_a53.dts:273 */
			phandle = < 0x6 >;                     /* in zephyr/boards/qemu/cortex_a53/qemu_cortex_a53.dts:280 */
		};
	};

	/* node '/ramfb' defined in zephyr/boards/qemu/cortex_a53/qemu_cortex_a53.dts:277 */
	ramfb0: ramfb {
		compatible = "qemu,ramfb";      /* in zephyr/boards/qemu/cortex_a53/qemu_cortex_a53.dts:278 */
		fwcfg = < &fwcfg0 >;            /* in zephyr/boards/qemu/cortex_a53/qemu_cortex_a53.dts:279 */
		memory-region = < &ramfb_mem >; /* in zephyr/boards/qemu/cortex_a53/qemu_cortex_a53.dts:280 */
		width = < 0x400 >;              /* in zephyr/boards/qemu/cortex_a53/qemu_cortex_a53.dts:281 */
		height = < 0x300 >;             /* in zephyr/boards/qemu/cortex_a53/qemu_cortex_a53.dts:282 */
		status = "okay";                /* in zephyr/boards/qemu/cortex_a53/qemu_cortex_a53.dts:283 */
	};
};
